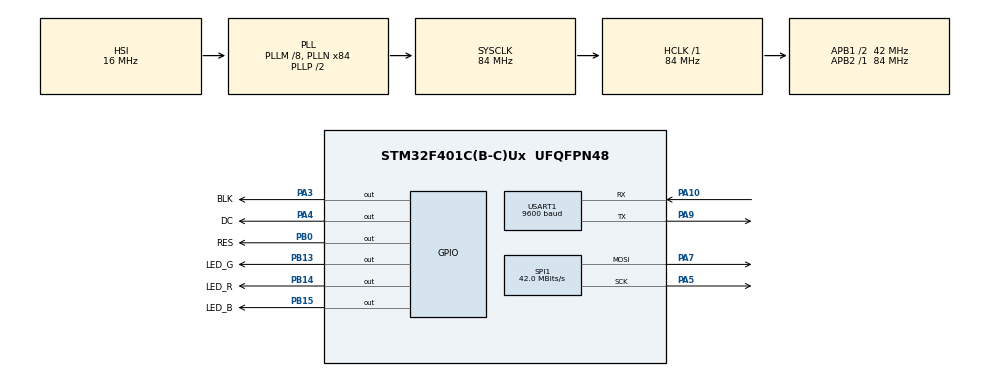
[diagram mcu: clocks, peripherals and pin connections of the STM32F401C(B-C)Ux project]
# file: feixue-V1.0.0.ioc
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Dma.Request0=SPI1_TX
Dma.SPI1_TX.0.Direction=DMA_MEMORY_TO_PERIPH
Dma.SPI1_TX.0.FIFOMode=DMA_FIFOMODE_DISABLE
Dma.SPI1_TX.0.Instance=DMA2_Stream3
Dma.SPI1_TX.0.MemDataAlignment=DMA_MDATAALIGN_HALFWORD
Dma.SPI1_TX.0.MemInc=DMA_MINC_ENABLE
Dma.SPI1_TX.0.Mode=DMA_NORMAL
Dma.SPI1_TX.0.PeriphDataAlignment=DMA_PDATAALIGN_HALFWORD
Dma.SPI1_TX.0.PeriphInc=DMA_PINC_DISABLE
Dma.SPI1_TX.0.Priority=DMA_PRIORITY_LOW
Mcu.Family=STM32F4
Mcu.Name=STM32F401C(B-C)Ux
Mcu.Package=UFQFPN48
NVIC.DMA2_Stream3_IRQn=true\:0\:0\:false\:false\:true\:false\:true
NVIC.PriorityGroup=NVIC_PRIORITYGROUP_4
NVIC.TIM1_UP_TIM10_IRQn=true\:1\:0\:true\:false\:true\:true\:true
NVIC.USART1_IRQn=true\:4\:0\:true\:false\:true\:true\:true
PA10.Mode=Asynchronous
PA10.Signal=USART1_RX
PA13.Mode=Serial_Wire
PA13.Signal=SYS_JTMS-SWDIO
PA14.Mode=Serial_Wire
PA14.Signal=SYS_JTCK-SWCLK
PA3.GPIO_Label=BLK
PA3.GPIO_PuPd=GPIO_PULLUP
PA3.GPIO_Speed=GPIO_SPEED_FREQ_HIGH
PA3.PinState=GPIO_PIN_SET
PA3.Signal=GPIO_Output
PA4.GPIO_Label=DC
PA4.GPIO_PuPd=GPIO_PULLUP
PA4.GPIO_Speed=GPIO_SPEED_FREQ_HIGH
PA4.PinState=GPIO_PIN_SET
PA4.Signal=GPIO_Output
PA5.Mode=TX_Only_Simplex_Unidirect_Master
PA5.Signal=SPI1_SCK
PA7.Mode=TX_Only_Simplex_Unidirect_Master
PA7.Signal=SPI1_MOSI
PA9.Mode=Asynchronous
PA9.Signal=USART1_TX
PB0.GPIO_Label=RES
PB0.GPIO_PuPd=GPIO_PULLUP
PB0.GPIO_Speed=GPIO_SPEED_FREQ_HIGH
PB0.PinState=GPIO_PIN_SET
PB0.Signal=GPIO_Output
PB13.GPIO_Label=LED_G
PB13.GPIO_PuPd=GPIO_PULLUP
PB13.GPIO_Speed=GPIO_SPEED_FREQ_VERY_HIGH
PB13.PinState=GPIO_PIN_RESET
PB13.Signal=GPIO_Output
PB14.GPIO_Label=LED_R
PB14.GPIO_PuPd=GPIO_PULLUP
PB14.GPIO_Speed=GPIO_SPEED_FREQ_VERY_HIGH
PB14.PinState=GPIO_PIN_RESET
PB14.Signal=GPIO_Output
PB15.GPIO_Label=LED_B
PB15.GPIO_PuPd=GPIO_PULLUP
PB15.GPIO_Speed=GPIO_SPEED_FREQ_VERY_HIGH
PB15.Signal=GPIO_Output
ProjectManager.HeapSize=0x200
ProjectManager.StackSize=0x400
ProjectManager.TargetToolchain=STM32CubeIDE
RCC.48MHZClocksFreq_Value=42000000
RCC.AHBFreq_Value=84000000
RCC.APB1CLKDivider=RCC_HCLK_DIV2
RCC.APB1Freq_Value=42000000
RCC.APB1TimFreq_Value=84000000
RCC.APB2Freq_Value=84000000
RCC.APB2TimFreq_Value=84000000
RCC.CortexFreq_Value=84000000
RCC.HCLKFreq_Value=84000000
RCC.HSE_VALUE=25000000
RCC.HSI_VALUE=16000000
RCC.LSE_VALUE=32768
RCC.PLLM=8
RCC.PLLN=84
RCC.SYSCLKFreq_VALUE=84000000
RCC.SYSCLKSource=RCC_SYSCLKSOURCE_PLLCLK
RCC.VCOOutputFreq_Value=168000000
SPI1.BaudRatePrescaler=SPI_BAUDRATEPRESCALER_2
SPI1.CLKPhase=SPI_PHASE_2EDGE
SPI1.CLKPolarity=SPI_POLARITY_HIGH
SPI1.CalculateBaudRate=42.0 MBits/s
SPI1.Direction=SPI_DIRECTION_2LINES
SPI1.Mode=SPI_MODE_MASTER
SPI1.VirtualType=VM_MASTER
TIM10.Period=1000
TIM10.Prescaler=83
USART1.BaudRate=9600
USART1.VirtualMode=VM_ASYNC
VP_TIM10_VS_ClockSourceINT.Mode=Enable_Timer
board=custom

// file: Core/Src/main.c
/* USER CODE BEGIN Header */
/**
  ******************************************************************************
  * @file           : main.c
  * @brief          : Main program body
  ******************************************************************************
  * @attention
  *
  * <h2><center>&copy; Copyright (c) 2020 STMicroelectronics.
  * All rights reserved.</center></h2>
  *
  * This software component is licensed by ST under BSD 3-Clause license,
  * the "License"; You may not use this file except in compliance with the
  * License. You may obtain a copy of the License at:
  *                        opensource.org/licenses/BSD-3-Clause
  *
  ******************************************************************************
  */
/* USER CODE END Header */
#include "main.h"
#include "dma.h"
#include "spi.h"
#include "tim.h"
#include "usart.h"
#include "gpio.h"

/* USER CODE BEGIN Includes */
#include "Feixue.h"
/* USER CODE END Includes */

void SystemClock_Config(void);

int main(void)
{

  /* MCU Configuration--------------------------------------------------------*/

  /* Reset of all peripherals, Initializes the Flash interface and the Systick. */
  HAL_Init();

  /* Configure the system clock */
  SystemClock_Config();

  /* Initialize all configured peripherals */
  MX_GPIO_Init();
  MX_DMA_Init();
  MX_TIM10_Init();
  MX_SPI1_Init();
  MX_USART1_UART_Init();
  /* USER CODE BEGIN 2 */
  setup();
  /* USER CODE END 2 */

  /* Infinite loop */
  while (1)
  {

    /* USER CODE BEGIN 3 */
	loop();

  }
  /* USER CODE END 3 */
}

void SystemClock_Config(void)
{
  RCC_OscInitTypeDef RCC_OscInitStruct = {0};
  RCC_ClkInitTypeDef RCC_ClkInitStruct = {0};

  /** Configure the main internal regulator output voltage
  */
  __HAL_RCC_PWR_CLK_ENABLE();
  __HAL_PWR_VOLTAGESCALING_CONFIG(PWR_REGULATOR_VOLTAGE_SCALE2);
  /** Initializes the RCC Oscillators according to the specified parameters
  * in the RCC_OscInitTypeDef structure.
  */
  RCC_OscInitStruct.OscillatorType = RCC_OSCILLATORTYPE_HSI;
  RCC_OscInitStruct.HSIState = RCC_HSI_ON;
  RCC_OscInitStruct.HSICalibrationValue = RCC_HSICALIBRATION_DEFAULT;
  RCC_OscInitStruct.PLL.PLLState = RCC_PLL_ON;
  RCC_OscInitStruct.PLL.PLLSource = RCC_PLLSOURCE_HSI;
  RCC_OscInitStruct.PLL.PLLM = 8;
  RCC_OscInitStruct.PLL.PLLN = 84;
  RCC_OscInitStruct.PLL.PLLP = RCC_PLLP_DIV2;
  RCC_OscInitStruct.PLL.PLLQ = 4;
  if (HAL_RCC_OscConfig(&RCC_OscInitStruct) != HAL_OK)
  {
    Error_Handler();
  }
  /** Initializes the CPU, AHB and APB buses clocks
  */
  RCC_ClkInitStruct.ClockType = RCC_CLOCKTYPE_HCLK|RCC_CLOCKTYPE_SYSCLK
                              |RCC_CLOCKTYPE_PCLK1|RCC_CLOCKTYPE_PCLK2;
  RCC_ClkInitStruct.SYSCLKSource = RCC_SYSCLKSOURCE_PLLCLK;
  RCC_ClkInitStruct.AHBCLKDivider = RCC_SYSCLK_DIV1;
  RCC_ClkInitStruct.APB1CLKDivider = RCC_HCLK_DIV2;
  RCC_ClkInitStruct.APB2CLKDivider = RCC_HCLK_DIV1;

  if (HAL_RCC_ClockConfig(&RCC_ClkInitStruct, FLASH_LATENCY_2) != HAL_OK)
  {
    Error_Handler();
  }
}

void Error_Handler(void)
{
  __disable_irq();
  while (1)
  {
  }
}

/************************ (C) COPYRIGHT STMicroelectronics *****END OF FILE****/
